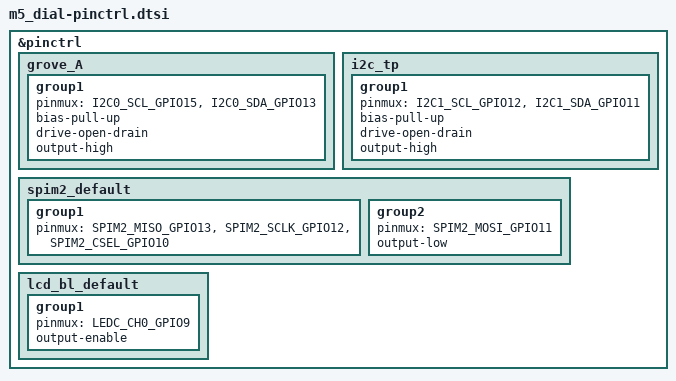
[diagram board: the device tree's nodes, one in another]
/*
 * Copyright (c) 2022 Espressif Systems (Shanghai) Co., Ltd.
 *
 * SPDX-License-Identifier: Apache-2.0
 */

#include <zephyr/dt-bindings/pinctrl/esp-pinctrl-common.h>
#include <dt-bindings/pinctrl/esp32s3-pinctrl.h>
#include <zephyr/dt-bindings/pinctrl/esp32s3-gpio-sigmap.h>

&pinctrl {
	grove_A: grove_A {
		group1 {
			pinmux = <I2C0_SCL_GPIO15>, <I2C0_SDA_GPIO13>;
			bias-pull-up;
			drive-open-drain;
			output-high;
		};
	};
	i2c_tp: i2c_tp {
		group1 {
			pinmux = <I2C1_SCL_GPIO12>, <I2C1_SDA_GPIO11>;
			bias-pull-up;
			drive-open-drain;
			output-high;
		};
	};

	spim2_default: spim2_default {
		group1 {
			pinmux = <SPIM2_MISO_GPIO13>,
					 <SPIM2_SCLK_GPIO12>,
					 <SPIM2_CSEL_GPIO10>;
		};
		group2 {
			pinmux = <SPIM2_MOSI_GPIO11>;
			output-low;
		};
	};
	lcd_bl_default: lcd_bl_default {
		group1 {
			pinmux = <LEDC_CH0_GPIO9>;
			output-enable;
		};
	};

};
